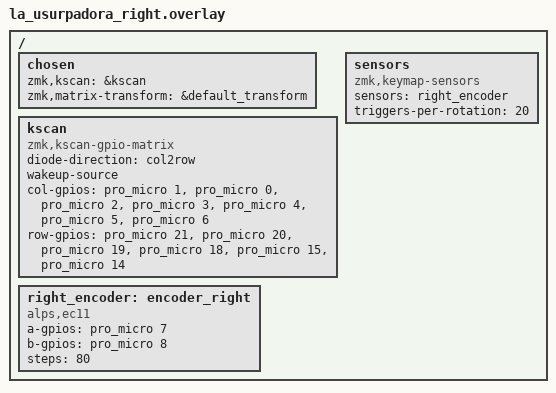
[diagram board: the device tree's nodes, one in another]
#include "la_usurpadora.dtsi"

/ {
    chosen {
        zmk,kscan = &kscan;
        zmk,matrix-transform = &default_transform;
    };

    kscan: kscan {
        compatible = "zmk,kscan-gpio-matrix";
        diode-direction = "col2row";
        wakeup-source;

        col-gpios
            = <&pro_micro 1 GPIO_ACTIVE_HIGH>
            , <&pro_micro 0 GPIO_ACTIVE_HIGH>
            , <&pro_micro 2 GPIO_ACTIVE_HIGH>
            , <&pro_micro 3 GPIO_ACTIVE_HIGH>
            , <&pro_micro 4 GPIO_ACTIVE_HIGH>
            , <&pro_micro 5 GPIO_ACTIVE_HIGH>
            , <&pro_micro 6 GPIO_ACTIVE_HIGH>
            ;

        row-gpios
            = <&pro_micro 21 (GPIO_ACTIVE_HIGH | GPIO_PULL_DOWN)>
            , <&pro_micro 20 (GPIO_ACTIVE_HIGH | GPIO_PULL_DOWN)>
            , <&pro_micro 19 (GPIO_ACTIVE_HIGH | GPIO_PULL_DOWN)>
            , <&pro_micro 18 (GPIO_ACTIVE_HIGH | GPIO_PULL_DOWN)>
            , <&pro_micro 15 (GPIO_ACTIVE_HIGH | GPIO_PULL_DOWN)>
            , <&pro_micro 14 (GPIO_ACTIVE_HIGH | GPIO_PULL_DOWN)>
            ;
    };

    right_encoder: encoder_right {
        compatible = "alps,ec11";
        a-gpios = <&pro_micro 7 (GPIO_ACTIVE_HIGH | GPIO_PULL_UP)>; 
        b-gpios = <&pro_micro 8 (GPIO_ACTIVE_HIGH | GPIO_PULL_UP)>; 
        steps = <80>; 
    };

    sensors: sensors {
        compatible = "zmk,keymap-sensors";
        sensors = <&right_encoder>;
        triggers-per-rotation = <20>;
    };
};
